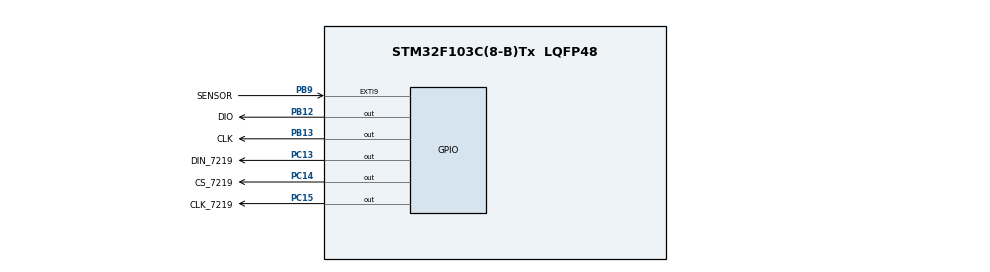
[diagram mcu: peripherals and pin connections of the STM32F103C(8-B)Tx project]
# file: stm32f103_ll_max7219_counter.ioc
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Mcu.Family=STM32F1
RCC.PLLSourceVirtual=RCC_PLLSOURCE_HSE
PD1-OSC_OUT.Mode=HSE-External-Oscillator
PB9.GPIO_Label=SENSOR
PC13-TAMPER-RTC.Signal=GPIO_Output
PD0-OSC_IN.Signal=RCC_OSC_IN
RCC.APB1CLKDivider=RCC_HCLK_DIV2
PC14-OSC32_IN.Signal=GPIO_Output
PB13.GPIO_Label=CLK
PB13.Signal=GPIO_Output
PC15-OSC32_OUT.GPIO_Label=CLK_7219
RCC.SYSCLKSource=RCC_SYSCLKSOURCE_PLLCLK
ProjectManager.StackSize=0x400
PD1-OSC_OUT.Signal=RCC_OSC_OUT
PA13.Signal=SYS_JTMS-SWDIO
ProjectManager.TargetToolchain=Makefile
RCC.HCLKFreq_Value=72000000
RCC.APB2TimFreq_Value=9000000
RCC.USBFreq_Value=72000000
PC15-OSC32_OUT.Signal=GPIO_Output
RCC.AHBFreq_Value=72000000
PD0-OSC_IN.Mode=HSE-External-Oscillator
board=custom
PC13-TAMPER-RTC.GPIO_Label=DIN_7219
RCC.PLLMUL=RCC_PLL_MUL9
PB12.GPIO_Label=DIO
RCC.APB2Freq_Value=4500000
PA14.Mode=Serial_Wire
PA13.Mode=Serial_Wire
Mcu.Name=STM32F103C(8-B)Tx
RCC.SYSCLKFreq_VALUE=72000000
Mcu.Package=LQFP48
PB9.Signal=GPXTI9
NVIC.EXTI9_5_IRQn=true\:0\:0\:false\:false\:true\:true\:true
PA14.Signal=SYS_JTCK-SWCLK
ProjectManager.HeapSize=0x200
NVIC.PriorityGroup=NVIC_PRIORITYGROUP_4
RCC.APB2CLKDivider=RCC_HCLK_DIV16
RCC.APB1TimFreq_Value=72000000
PC14-OSC32_IN.GPIO_Label=CS_7219
RCC.APB1Freq_Value=36000000
PB12.Signal=GPIO_Output

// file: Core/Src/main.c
/* USER CODE BEGIN Header */
/**
  ******************************************************************************
  * @file           : main.c
  * @brief          : Main program body
  ******************************************************************************
  * @attention
  *
  * <h2><center>&copy; Copyright (c) 2020 STMicroelectronics.
  * All rights reserved.</center></h2>
  *
  * This software component is licensed by ST under BSD 3-Clause license,
  * the "License"; You may not use this file except in compliance with the
  * License. You may obtain a copy of the License at:
  *                        opensource.org/licenses/BSD-3-Clause
  *
  ******************************************************************************
  */
/* USER CODE END Header */
#include "main.h"
#include "gpio.h"

/* USER CODE BEGIN Includes */
#include "max7219display.h"
/* USER CODE END Includes */

/* USER CODE BEGIN PV */
/* Private variables ---------------------------------------------------------*/
uint32_t tim_counter; // external for timer - extern uint16_t tim_counter;
/* USER CODE END PV */

void SystemClock_Config(void);
/* USER CODE BEGIN PFP */
/* Private function prototypes -----------------------------------------------*/
__STATIC_INLINE void DelayMicro(uint32_t __IO micros)
{
  micros *=(SystemCoreClock/1000000)/5;
  while(micros--);
}

/* USER CODE END PFP */

int main(void)
{

  /* MCU Configuration--------------------------------------------------------*/

  /* Reset of all peripherals, Initializes the Flash interface and the Systick. */

  LL_APB2_GRP1_EnableClock(LL_APB2_GRP1_PERIPH_AFIO);
  LL_APB1_GRP1_EnableClock(LL_APB1_GRP1_PERIPH_PWR);

  NVIC_SetPriorityGrouping(NVIC_PRIORITYGROUP_4);

  /* System interrupt init*/

  /** NOJTAG: JTAG-DP Disabled and SW-DP Enabled
  */
  LL_GPIO_AF_Remap_SWJ_NOJTAG();

  /* Configure the system clock */
  SystemClock_Config();

  /* Initialize all configured peripherals */
  MX_GPIO_Init();

  /* Infinite loop */
  while (1)
  {

    /* USER CODE BEGIN 3 */
    tim_counter=0;
    LL_mDelay(500);
    showNumberDec(tim_counter, 0, 8, 0);
  }
  /* USER CODE END 3 */
}

void SystemClock_Config(void)
{
  LL_FLASH_SetLatency(LL_FLASH_LATENCY_2);
  while(LL_FLASH_GetLatency()!= LL_FLASH_LATENCY_2)
  {
  }
  LL_RCC_HSE_Enable();

   /* Wait till HSE is ready */
  while(LL_RCC_HSE_IsReady() != 1)
  {

  }
  LL_RCC_PLL_ConfigDomain_SYS(LL_RCC_PLLSOURCE_HSE_DIV_1, LL_RCC_PLL_MUL_9);
  LL_RCC_PLL_Enable();

   /* Wait till PLL is ready */
  while(LL_RCC_PLL_IsReady() != 1)
  {

  }
  LL_RCC_SetAHBPrescaler(LL_RCC_SYSCLK_DIV_1);
  LL_RCC_SetAPB1Prescaler(LL_RCC_APB1_DIV_2);
  LL_RCC_SetAPB2Prescaler(LL_RCC_APB2_DIV_16);
  LL_RCC_SetSysClkSource(LL_RCC_SYS_CLKSOURCE_PLL);

   /* Wait till System clock is ready */
  while(LL_RCC_GetSysClkSource() != LL_RCC_SYS_CLKSOURCE_STATUS_PLL)
  {

  }
  LL_Init1msTick(72000000);
  LL_SetSystemCoreClock(72000000);
}

void Error_Handler(void)
{
  while(1)
  {
  }
}

/************************ (C) COPYRIGHT STMicroelectronics *****END OF FILE****/
